# earlgrey register map
Vendor: lowRISC; File version: 0.1
CPU: ibex rev01, little endian, no MPU, no FPU, VTOR, 2 interrupt priority bits, 2 interrupts
Registers are 32-bit, read-write, no defined reset value unless marked. A register's access mark holds for its fields unless they carry their own. Offsets are from the block's base; [hi:lo] are bit positions; {n}, {i} and the like mark numbered series; 'fields as' and 'values as' point back to an identical list.

## SYSRST_CTRL_AON — Manages board-level reset sequencing, interfaces reset and power manager
Base 0x40430000
0x40 REGWEN — Configuration write enable control register
  [0] write_en — config write enable.0: cfg is locked(not writable); 1: cfg is not locked(writable)
0x44 EC_RST_CTL — EC reset control register
  [15:0] ec_rst_pulse — Configure the debounce timer in number of clock cycles.Each step is 5 us for a 200 kHz clock.The signal must exceed the debounce time by at least one clock cycle to be detected.
0x48 ULP_AC_DEBOUNCE_CTL — Ultra low power AC debounce control register
  [15:0] ulp_ac_debounce_timer — Configure the debounce timer for the AC input in number of clock cycles.Each step is 5 us for a 200 kHz clock.The signal must exceed the debounce time by at least one clock cycle to be detected.
0x4C ULP_LID_DEBOUNCE_CTL — Ultra low power lid debounce control register
  [15:0] ulp_lid_debounce_timer — Configure the debounce timer for the lid in number of clock cycles.Each step is 5 us for a 200 kHz clock.The signal must exceed the debounce time by at least one clock cycle to be detected.
0x50 ULP_PWRB_DEBOUNCE_CTL — Ultra low power pwrb debounce control register
  [15:0] ulp_pwrb_debounce_timer — Configure the debounce timer for the power button in number of clock cycles.Each step is 5 us for a 200 kHz clock.The signal must exceed the debounce time by at least one clock cycle to be detected.
0x54 ULP_CTL — Ultra low power control register
  [0] ulp_enable — 0: disable ULP wakeup feature and reset the ULP FSM; 1: enable ULP wakeup feature
0x58 ULP_STATUS — Ultra low power status
  [0] ulp_wakeup — 0: ULP wakeup not detected; 1: ULP wakeup event is detected
0x5C WKUP_STATUS — wakeup status
  [0] wakeup_sts — 0: wakeup event not detected; 1: wakeup event is detected
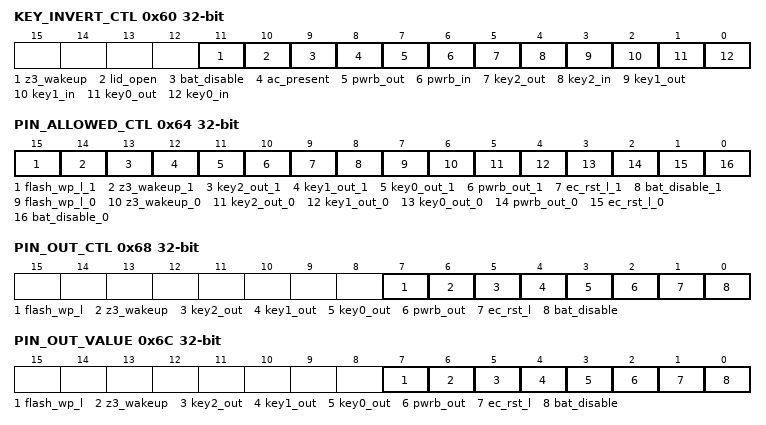
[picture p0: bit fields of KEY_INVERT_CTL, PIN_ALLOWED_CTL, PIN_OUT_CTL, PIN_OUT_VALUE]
0x60 KEY_INVERT_CTL — configure key input output invert property
  [11] z3_wakeup — 0: don't invert; 1: invert
  [10] lid_open — 0: don't invert; 1: invert
  [9] bat_disable — 0: don't invert; 1: invert
  [8] ac_present — 0: don't invert; 1: invert
  [7] pwrb_out — 0: don't invert; 1: invert
  [6] pwrb_in — 0: don't invert; 1: invert
  [5] key2_out — 0: don't invert; 1: invert
  [4] key2_in — 0: don't invert; 1: invert
  [3] key1_out — 0: don't invert; 1: invert
  [2] key1_in — 0: don't invert; 1: invert
  [1] key0_out — 0: don't invert; 1: invert
  [0] key0_in — 0: don't invert; 1: invert
0x64 PIN_ALLOWED_CTL — This register determines which override values are allowed for a given output.If an override value programmed via !!PIN_OUT_VALUE is not configured as an allowed value,it will not have any effect.
  [15] flash_wp_l_1 — 0: not allowed; 1: allowed
  [14] z3_wakeup_1 — 0: not allowed; 1: allowed
  [13] key2_out_1 — 0: not allowed; 1: allowed
  [12] key1_out_1 — 0: not allowed; 1: allowed
  [11] key0_out_1 — 0: not allowed; 1: allowed
  [10] pwrb_out_1 — 0: not allowed; 1: allowed
  [9] ec_rst_l_1 — 0: not allowed; 1: allowed
  [8] bat_disable_1 — 0: not allowed; 1: allowed
  [7] flash_wp_l_0 — 0: not allowed; 1: allowed
  [6] z3_wakeup_0 — 0: not allowed; 1: allowed
  [5] key2_out_0 — 0: not allowed; 1: allowed
  [4] key1_out_0 — 0: not allowed; 1: allowed
  [3] key0_out_0 — 0: not allowed; 1: allowed
  [2] pwrb_out_0 — 0: not allowed; 1: allowed
  [1] ec_rst_l_0 — 0: not allowed; 1: allowed
  [0] bat_disable_0 — 0: not allowed; 1: allowed
0x68 PIN_OUT_CTL — Enables the override function for a specific pin.
  [7] flash_wp_l — 0: disable override; 1: enable override
  [6] z3_wakeup — 0: disable override; 1: enable override
  [5] key2_out — 0: disable override; 1: enable override
  [4] key1_out — 0: disable override; 1: enable override
  [3] key0_out — 0: disable override; 1: enable override
  [2] pwrb_out — 0: disable override; 1: enable override
  [1] ec_rst_l — 0: disable override; 1: enable override
  [0] bat_disable — 0: disable override; 1: enable override
0x6C PIN_OUT_VALUE — Sets the pin override value. Note that only the valuesconfigured as 'allowed' in !!PIN_ALLOWED_CTL will havean effect. Otherwise the pin value will not be overridden.
  [7] flash_wp_l — 0: override to 1b0; 1: override to 1b1
  [6] z3_wakeup — 0: override to 1b0; 1: override to 1b1
  [5] key2_out — 0: override to 1b0; 1: override to 1b1
  [4] key1_out — 0: override to 1b0; 1: override to 1b1
  [3] key0_out — 0: override to 1b0; 1: override to 1b1
  [2] pwrb_out — 0: override to 1b0; 1: override to 1b1
  [1] ec_rst_l — 0: override to 1b0; 1: override to 1b1
  [0] bat_disable — 0: override to 1b0; 1: override to 1b1
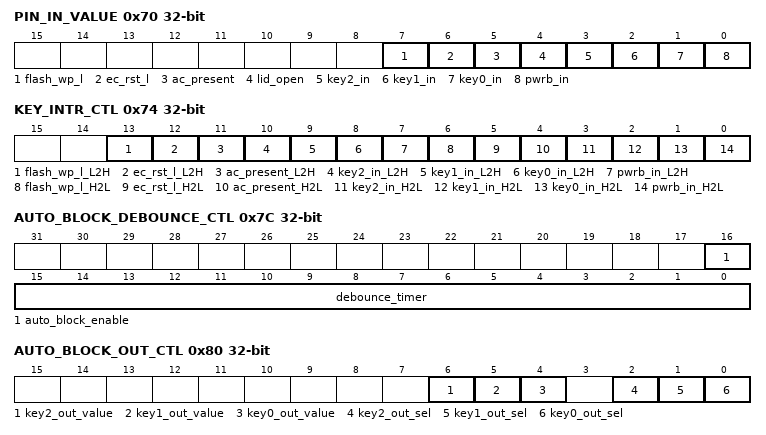
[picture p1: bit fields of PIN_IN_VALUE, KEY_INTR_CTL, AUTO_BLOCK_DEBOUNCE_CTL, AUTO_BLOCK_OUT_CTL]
0x70 PIN_IN_VALUE ro — For SW to read the sysrst_ctrl inputs like GPIO
  [7] flash_wp_l — raw flash_wp_l value; before the invert logic
  [6] ec_rst_l — raw ec_rst_l value; before the invert logic
  [5] ac_present — raw ac_present value; before the invert logic
  [4] lid_open — raw lid_open value; before the invert logic
  [3] key2_in — raw key2_in value; before the invert logic
  [2] key1_in — raw key1_in value; before the invert logic
  [1] key0_in — raw key0_in value; before the invert logic
  [0] pwrb_in — raw pwrb_in value; before the invert logic
0x74 KEY_INTR_CTL — Define the keys or inputs that can trigger the interrupt
  [13] flash_wp_l_L2H — 0: disable, 1: enable
  [12] ec_rst_l_L2H — 0: disable, 1: enable
  [11] ac_present_L2H — 0: disable, 1: enable
  [10] key2_in_L2H — 0: disable, 1: enable
  [9] key1_in_L2H — 0: disable, 1: enable
  [8] key0_in_L2H — 0: disable, 1: enable
  [7] pwrb_in_L2H — 0: disable, 1: enable
  [6] flash_wp_l_H2L — 0: disable, 1: enable
  [5] ec_rst_l_H2L — 0: disable, 1: enable
  [4] ac_present_H2L — 0: disable, 1: enable
  [3] key2_in_H2L — 0: disable, 1: enable
  [2] key1_in_H2L — 0: disable, 1: enable
  [1] key0_in_H2L — 0: disable, 1: enable
  [0] pwrb_in_H2L — 0: disable, 1: enable
0x78 KEY_INTR_DEBOUNCE_CTL — Debounce timer control register for key-triggered interrupt
  [15:0] debounce_timer — Define the timer value so that the key or input is not oscillating in clock cycles.Each step is 5 us for a 200 kHz clock.The signal must exceed the debounce time by at least one clock cycle to be detected.
0x7C AUTO_BLOCK_DEBOUNCE_CTL — Debounce timer control register for pwrb_in H2L transition
  [16] auto_block_enable — 0: disable, 1: enable
  [15:0] debounce_timer — Define the timer value so that the pwrb_in is not oscillating in clock cycles.Each step is 5 us for a 200 kHz clock.The signal must exceed the debounce time by at least one clock cycle to be detected.
0x80 AUTO_BLOCK_OUT_CTL — configure the key outputs to auto-override and their value
  [6] key2_out_value — 0: override to 1'b0; 1: override to 1'b1
  [5] key1_out_value — 0: override to 1'b0; 1: override to 1'b1
  [4] key0_out_value — 0: override to 1'b0; 1: override to 1'b1
  [2] key2_out_sel — 0: disable auto-block; 1: enable auto-block
  [1] key1_out_sel — 0: disable auto-block; 1: enable auto-block
  [0] key0_out_sel — 0: disable auto-block; 1: enable auto-block
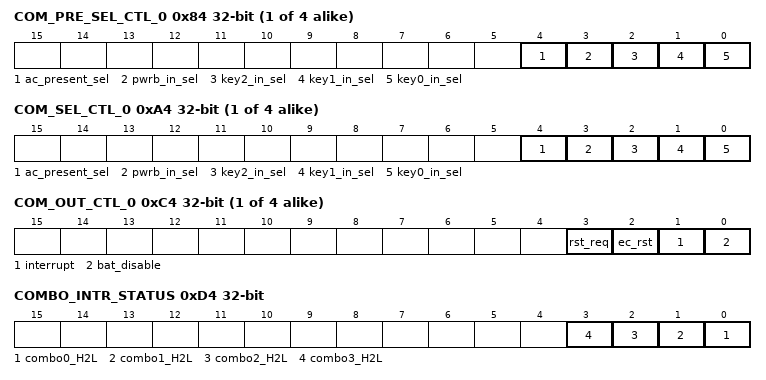
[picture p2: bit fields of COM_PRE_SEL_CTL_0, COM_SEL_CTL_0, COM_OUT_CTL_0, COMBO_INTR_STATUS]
{0x84+4i} COM_PRE_SEL_CTL_{i} (i=0..3) — To define the keys that define the pre-condition of the combo[0]: key0_in_sel[1]: key1_in_sel[2]: key2_in_sel[3]: pwrb_in_sel[4]: ac_present_selHW will start matching the combo as defined by !!COM_SEL_CTL if this precondition is fulfilled.If no keys are configured for the pre-condition, the pre-condition always evaluates to true.The debounce timing is defined via !!KEY_INTR_DEBOUNCE_CTL whereas the pre-condition pressed timing is defined via !!COM_PRE_DET_CTL.
  [4] ac_present_sel — 0: disable, 1: enable
  [3] pwrb_in_sel — 0: disable, 1: enable
  [2] key2_in_sel — 0: disable, 1: enable
  [1] key1_in_sel — 0: disable, 1: enable
  [0] key0_in_sel — 0: disable, 1: enable
{0x94+4i} COM_PRE_DET_CTL_{i} (i=0..3) — To define the duration that the combo pre-condition should be pressed0-60s, each step is 5us(200KHz clock)
  [31:0] precondition_timer_{i} — 0-60s, each step is 5us(200KHz clock)
{0xA4+4i} COM_SEL_CTL_{i} (i=0..3) — To define the keys that trigger the combo[0]: key0_in_sel[1]: key1_in_sel[2]: key2_in_sel[3]: pwrb_in_sel[4]: ac_present_selHW will detect H2L transition in the combo use case.Optionally, a pre-condition can be configured for the combo detection via !!COM_PRE_SEL_CTL.If no keys are configured for the combo, the combo detection is disabled.The debounce timing is defined via !!KEY_INTR_DEBOUNCE_CTL whereas the key-pressed timing is defined via !!COM_DET_CTL.
  fields as COM_PRE_SEL_CTL_0
{0xB4+4i} COM_DET_CTL_{i} (i=0..3) — To define the duration that the combo should be pressed0-60s, each step is 5us(200KHz clock)
  [31:0] detection_timer_{i} — 0-60s, each step is 5us(200KHz clock)
{0xC4+4i} COM_OUT_CTL_{i} (i=0..3) — To define the actions once the combo is detected[0]: bat_disable[1]: interrupt (to OpenTitan processor)[2]: ec_rst (for Embedded Controller)[3]: rst_req (to OpenTitan reset manager)
  [3] rst_req — 0: disable, 1: enable
  [2] ec_rst — 0: disable, 1: enable
  [1] interrupt — 0: disable, 1: enable
  [0] bat_disable — 0: disable, 1: enable
0xD4 COMBO_INTR_STATUS — Combo interrupt source. These registers will only be set if theinterrupt action is configured in the corresponding !!COM_OUT_CTL register.
  [n] combo{n}_H2L (n=0..3) — 0: case not detected;1: case detected
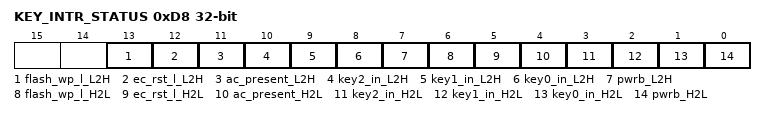
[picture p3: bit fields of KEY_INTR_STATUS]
0xD8 KEY_INTR_STATUS — key interrupt source
  [13] flash_wp_l_L2H — 0: case not detected;1: case detected
  [12] ec_rst_l_L2H — 0: case not detected;1: case detected
  [11] ac_present_L2H — 0: case not detected;1: case detected
  [10] key2_in_L2H — 0: case not detected;1: case detected
  [9] key1_in_L2H — 0: case not detected;1: case detected
  [8] key0_in_L2H — 0: case not detected;1: case detected
  [7] pwrb_L2H — 0: case not detected;1: case detected
  [6] flash_wp_l_H2L — 0: case not detected;1: case detected
  [5] ec_rst_l_H2L — 0: case not detected;1: case detected
  [4] ac_present_H2L — 0: case not detected;1: case detected
  [3] key2_in_H2L — 0: case not detected;1: case detected
  [2] key1_in_H2L — 0: case not detected;1: case detected
  [1] key0_in_H2L — 0: case not detected;1: case detected
  [0] pwrb_H2L — 0: case not detected;1: case detected
